# ATUC128D3 device description
Architecture: AVR32_UC3; Family: AVR UC3
Registers are 32-bit, read-write, reset 0x0 unless marked. A register's access mark holds for its fields unless they carry their own. Offsets are from the block's base; [hi:lo] are bit positions; {n}, {i} and the like mark numbered series; 'fields as' and 'values as' point back to an identical list.

## SCIF — System Control Interface
Instances: SCIF 0xffff5800
Parameters: SCIF_ACCESS_KEY=0xAA
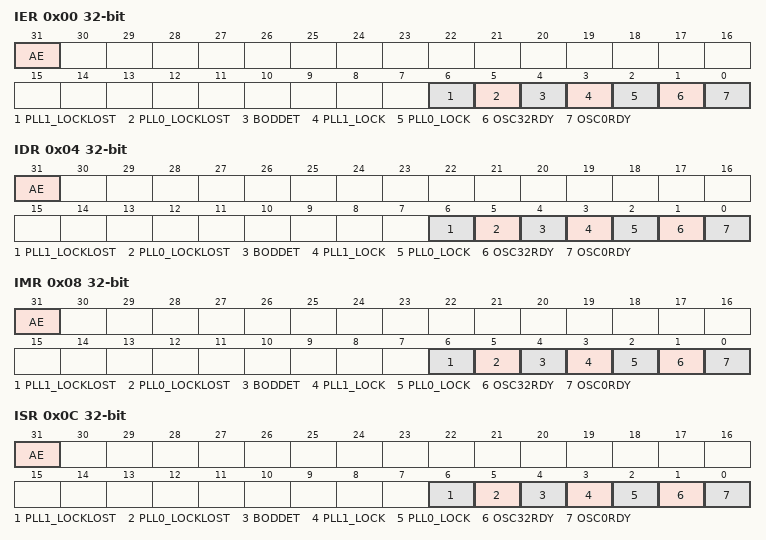
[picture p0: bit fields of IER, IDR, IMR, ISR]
0x00 IER wo — Interrupt Enable Register
  [31] AE, [6] PLL1_LOCKLOST, [5] PLL0_LOCKLOST, [4] BODDET, [3] PLL1_LOCK, [2] PLL0_LOCK, [1] OSC32RDY, [0] OSC0RDY
0x04 IDR wo — Interrupt Disable Register
  fields as IER
0x08 IMR ro — Interrupt Mask Register
  fields as IER
0x0C ISR ro — Interrupt Status Register
  fields as IER
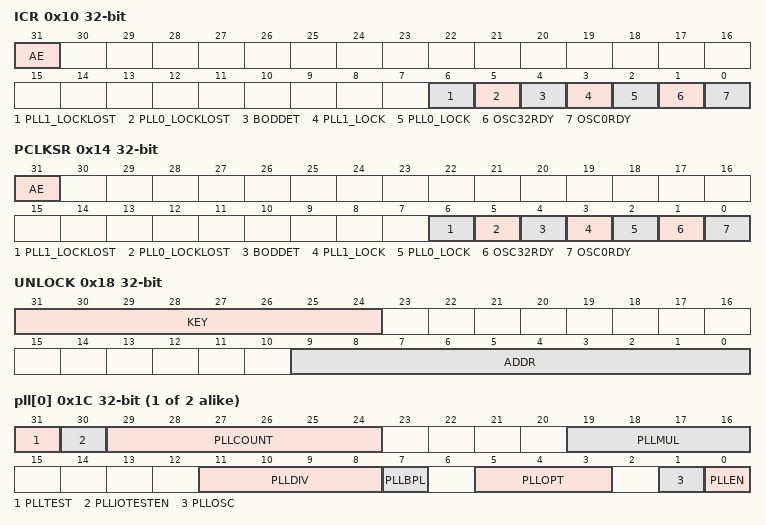
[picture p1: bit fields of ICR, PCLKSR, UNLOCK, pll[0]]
0x10 ICR wo — Interrupt Clear Register
  fields as IER
0x14 PCLKSR ro — Power and Clocks Status Register
  fields as IER
0x18 UNLOCK wo
  [31:24] KEY — Unlock Key
  [9:0] ADDR — Unlock Address
{0x1C+4i} pll[{i}] (i=0..1) access not given
  [31] PLLTEST
  [30] PLLIOTESTEN — PLL IO Test Enable
  [29:24] PLLCOUNT
  [19:16] PLLMUL — PLL Multiply factor
  [11:8] PLLDIV — PLL Division factor
  [7] PLLBPL — PLL Bypass Lock
  [5:3] PLLOPT — PLL Option
  [1] PLLOSC — PLL Oscillator select
    0=OSC0; 1=OSC1
  [0] PLLEN — PLL Enable
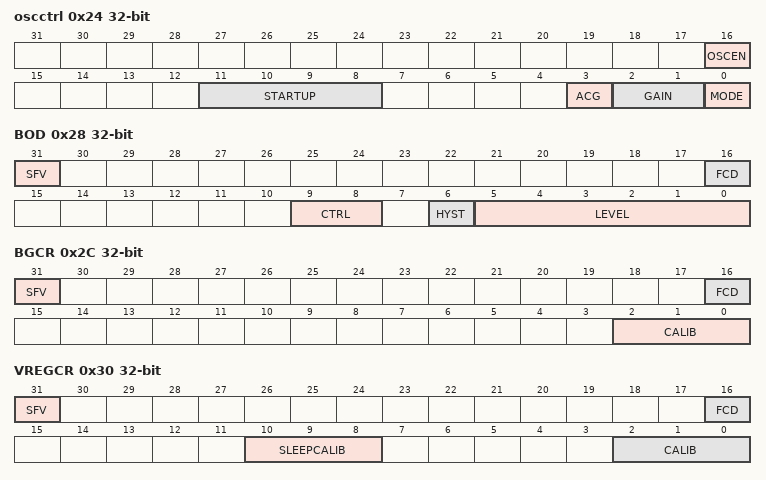
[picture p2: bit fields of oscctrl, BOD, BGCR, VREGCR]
0x24 oscctrl access not given
  [16] OSCEN — Oscillator Enable
  [11:8] STARTUP — Oscillator Start-up Time
  [3] ACG — Automatic Gain Control
  [2:1] GAIN
  [0] MODE — Oscillator Mode
    0=EXT_CLOCK; 1=CRYSTAL_ACG; 2=CRYSTAL_NO_ACG
0x28 BOD — 1.8V BOD Control Register
  [31] SFV — Store final value
  [16] FCD — BOD Fuse calibration done
  [9:8] CTRL — BOD Control
    0=OFF1; 1=ENABLED; 2=ENABLED_NORESET; 3=OFF2
  [6] HYST — BOD Hysteresis
  [5:0] LEVEL — BOD Level
0x2C BGCR — Bandgap Calibration Register
  [31] SFV — Store Final Value
  [16] FCD — Flash Calibration Done
  [2:0] CALIB — Calibration value
0x30 VREGCR — Voltage Regulator Calibration Register
  [31] SFV — Store Final Value
  [16] FCD — Flash calibration done
  [10:8] SLEEPCALIB — Voltage Regulator Sleep Calibration
  [2:0] CALIB — Voltage Regulator Calibration
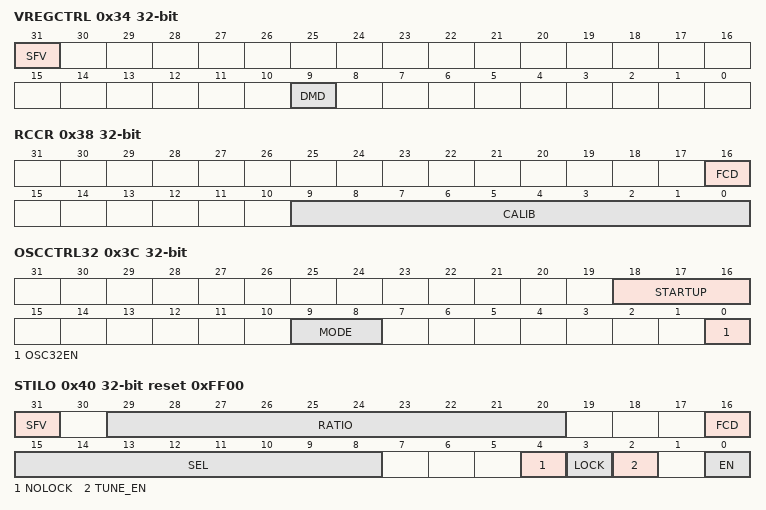
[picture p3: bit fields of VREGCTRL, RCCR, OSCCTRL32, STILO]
0x34 VREGCTRL — Voltage Regulator Control Register
  [31] SFV — Store Final Value
  [9] DMD — Deep Mode disable
0x38 RCCR — RCSYS Calibration Register
  [16] FCD — Flash Calibration Done
  [9:0] CALIB — Calibration Value
0x3C OSCCTRL32 — 32KHz Oscillator Control Register
  [18:16] STARTUP — 32KHz Oscillator Startup Time
  [9:8] MODE — 32KHz Oscillator Mode
    0=EXT_CLOCK; 1=CRYSTAL_ACG; 2=CRYSTAL_NO_ACG
  [0] OSC32EN — Enable the 32KHz oscillator
0x40 STILO reset 0xFF00
  [31] SFV — Store final value
  [29:20] RATIO — Target clock ratio
  [16] FCD — Fuse calibration done
  [15:8] SEL — Margin selection
  [4] NOLOCK — No lock on frequency
  [3] LOCK — Lock on frequency
  [2] TUNE_EN — Fuse calibration done
  [0] EN — STILO enable bit
0x44 RC120MCR — 120MHz RC Oscillator Configuration Register
  [0] EN — Enable bit
{0x48+4i} gplp[{i}] (i=0..1) access not given
  [31:0] GPLP — General Purpose Low Power
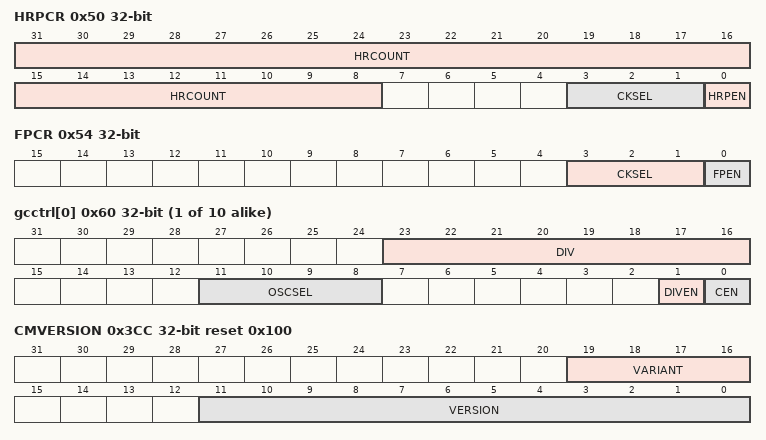
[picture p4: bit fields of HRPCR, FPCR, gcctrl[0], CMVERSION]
0x50 HRPCR — High Resolution Prescaler Control Register
  [31:8] HRCOUNT — High Resolution Counter
  [3:1] CKSEL — Clock Input Selection
  [0] HRPEN — High Resolution Prescaler Enable
0x54 FPCR — Fractionnal Prescaler Control Register
  [3:1] CKSEL — Clock Input Selection
  [0] FPEN — High Resolution Prescaler Enable
0x58 FPMUL — Fractionnal Prescaler Multiplier Register
  [19:0] FPMUL — Fractional Prescaler Multiplication Factor
0x5C FPDIV — Fractionnal Prescaler Divider Register
  [19:0] FPDIV — Fractional Prescaler Division Factor
{0x60+4i} gcctrl[{i}] (i=0..9) access not given
  [23:16] DIV — Division Factor
  [11:8] OSCSEL — Clock Select
  [1] DIVEN — Divide enable
  [0] CEN — Clock Enable
0x3CC CMVERSION ro reset 0x100 — Common Module Version Register
  [19:16] VARIANT — Variant number
  [11:0] VERSION — Version number
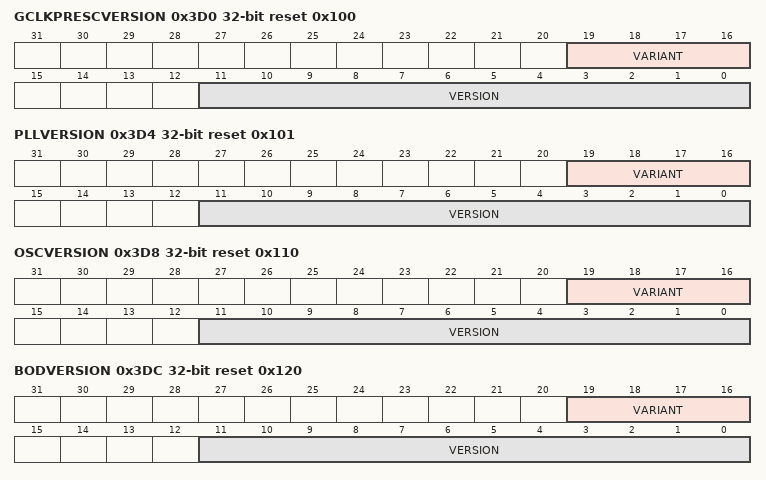
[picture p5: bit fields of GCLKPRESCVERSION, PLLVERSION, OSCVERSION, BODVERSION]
0x3D0 GCLKPRESCVERSION ro reset 0x100 — Generic Clock Prescaler Version Register
  [19:16] VARIANT — Variant number
  [11:0] VERSION — Version number
0x3D4 PLLVERSION ro reset 0x101 — PLL Interface Version Register
  [19:16] VARIANT — Variant number
  [11:0] VERSION — Version number
0x3D8 OSCVERSION ro reset 0x110 — Oscillator Interface Version Register
  [19:16] VARIANT — Variant number
  [11:0] VERSION — Version number
0x3DC BODVERSION ro reset 0x120 — 1.8V BOD Interface Version Register
  [19:16] VARIANT — Variant number
  [11:0] VERSION — Version number
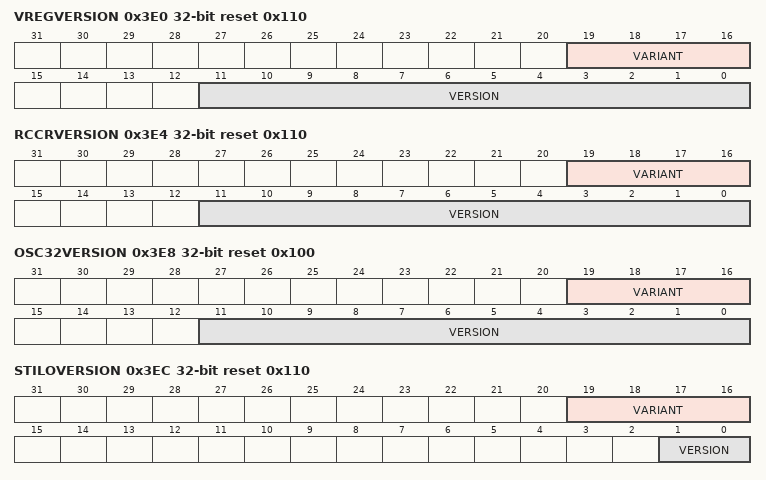
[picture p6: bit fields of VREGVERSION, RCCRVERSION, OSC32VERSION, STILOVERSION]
0x3E0 VREGVERSION ro reset 0x110 — Voltage Regulator Interface Version Register
  [19:16] VARIANT — Variant number
  [11:0] VERSION — Version number
0x3E4 RCCRVERSION ro reset 0x110 — RCSYS Interface Version Register
  [19:16] VARIANT — Variant number
  [11:0] VERSION — Version number
0x3E8 OSC32VERSION ro reset 0x100 — 32kHz Oscillator Interface Version Register
  [19:16] VARIANT — Variant number
  [11:0] VERSION — Version number
0x3EC STILOVERSION ro reset 0x110
  [19:16] VARIANT — Variant number
  [1:0] VERSION — Version number
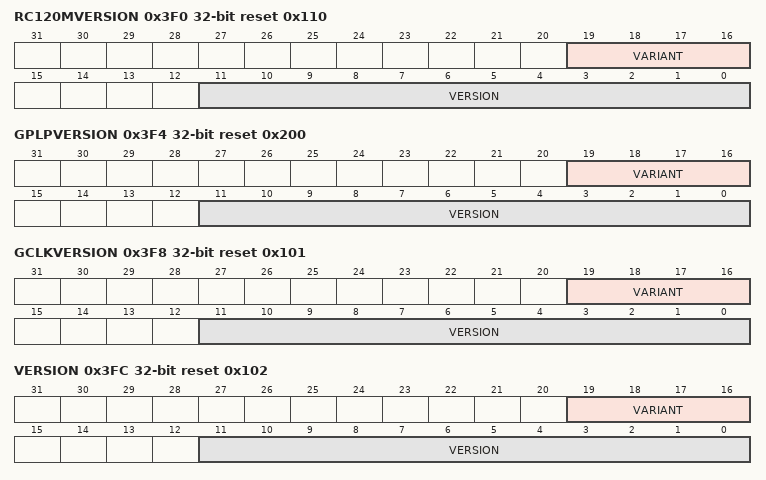
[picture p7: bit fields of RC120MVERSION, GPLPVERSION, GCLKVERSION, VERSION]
0x3F0 RC120MVERSION ro reset 0x110
  [19:16] VARIANT — Variant number
  [11:0] VERSION — Version number
0x3F4 GPLPVERSION ro reset 0x200
  [19:16] VARIANT — Variant number
  [11:0] VERSION — Version number
0x3F8 GCLKVERSION ro reset 0x101 — Generic Clock Interface Version Register
  [19:16] VARIANT — Variant number
  [11:0] VERSION — Version number
0x3FC VERSION ro reset 0x102 — SCIF Version Register
  [19:16] VARIANT, [11:0] VERSION
